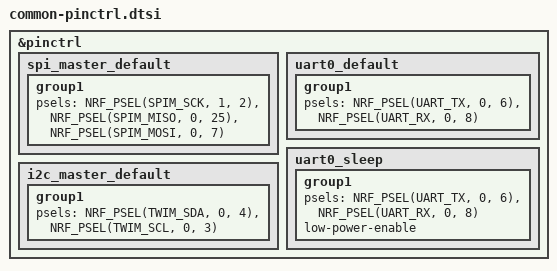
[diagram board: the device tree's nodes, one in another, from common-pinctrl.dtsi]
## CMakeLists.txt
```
#
# Copyright (c) 2018 Nordic Semiconductor
#
# SPDX-License-Identifier: LicenseRef-Nordic-5-Clause
#
cmake_minimum_required(VERSION 3.20.0)

find_package(Zephyr REQUIRED HINTS $ENV{ZEPHYR_BASE})
project(peripheral_uart)

# NORDIC SDK APP START
target_sources(app PRIVATE
  src/main.c
  src/spi.c
  src/BLE.c
  src/timer.c
  src/data.c
)

# NORDIC SDK APP END
```

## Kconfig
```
# Merged Kconfig for chronos-ble-uart project
# This provides menuconfig options for both timing control and BLE features

source "Kconfig.zephyr"

menu "Chronos BLE UART Configuration"

# BLE UART Service Configuration (from peripheral_uart)
config BT_NUS_THREAD_STACK_SIZE
	int "BLE UART thread stack size"
	default 1024
	help
	  Stack size used in each of the two threads handling BLE UART communication

config BT_NUS_UART_BUFFER_SIZE
	int "UART payload buffer element size"
	default 40
	help
	  Size of the payload buffer in each RX and TX FIFO element
	  Increase this if you need to send larger chunks of data

config BT_NUS_SECURITY_ENABLED
	bool "Enable BLE security"
	default y
	select BT_SMP
	help
	  Enable BLE security for the UART service
	  This includes pairing and bonding support

config BT_NUS_UART_RX_WAIT_TIME
	int "Timeout for UART RX complete event"
	default 50000
	help
	  Wait for RX complete event time in microseconds

# Chronos Timing Control Configuration (new section)
menu "Timing Control Configuration"

config CHRONOS_STIM_TIMER_US
	int "Stimulation timer period (microseconds)"
	default 4000000
	help
	  Time between stimulation events in microseconds
	  Default is 4 seconds (4000000 us)

config CHRONOS_EVENT1_OFFSET_US
	int "Event 1 offset from main event (microseconds)"
	default 1000000
	help
	  Time delay for first event after main stimulation

config CHRONOS_EVENT2_OFFSET_US
	int "Event 2 offset from event 1 (microseconds)"
	default 1000000
	help
	  Time delay for second event after event 1

config CHRONOS_EVENT3_OFFSET_US
	int "Event 3 offset from event 2 (microseconds)"
	default 1000000
	help
	  Time delay for third event after event 2

config CHRONOS_USE_PPI
	bool "Use PPI for hardware-timed events"
	default n
	help
	  Use Programmable Peripheral Interconnect for precise timing
	  This reduces CPU involvement and improves timing accuracy

endmenu # Timing Control Configuration

# Storage configuration (auto-selected based on hardware)
config SETTINGS
	default y

config ZMS
	default y if (SOC_FLASH_NRF_RRAM || SOC_FLASH_NRF_MRAM)
	help
	  Use Zephyr Memory Storage for newer flash types

config NVS
	default y if !(SOC_FLASH_NRF_RRAM || SOC_FLASH_NRF_MRAM)
	help
	  Use Non-Volatile Storage for traditional flash

endmenu # Chronos BLE UART Configuration
```

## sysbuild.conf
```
# Sysbuild configuration for nRF5340 dual-core Bluetooth application
# Compatible with nRF Connect SDK v3.0.2

# =============================================================================
# Network Core Configuration
# =============================================================================

# Enable the network core with Bluetooth controller
# This tells sysbuild to build the IPC radio image for the network core
SB_CONFIG_NETCORE_IPC_RADIO=y

# Use HCI IPC for Bluetooth communication between cores
# This enables the Bluetooth host (app core) to controller (net core) interface
SB_CONFIG_NETCORE_IPC_RADIO_BT_HCI_IPC=y

# =============================================================================
# Build Options
# =============================================================================

# Build the network core image
# This ensures both cores are programmed
SB_CONFIG_NETCORE_APP_UPDATE=y

# =============================================================================
# Optional: Bootloader Configuration
# =============================================================================

# For now, we're not using MCUboot
# Enable these later when you need firmware update capability
SB_CONFIG_BOOTLOADER_MCUBOOT=n
```

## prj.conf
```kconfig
#
# Copyright (c) 2018 Nordic Semiconductor
#
# SPDX-License-Identifier: LicenseRef-Nordic-5-Clause
#
##############################################################################
# BLE STACK
##############################################################################
# Enable the UART driver
CONFIG_UART_ASYNC_API=y
CONFIG_NRFX_UARTE0=y
CONFIG_SERIAL=y

CONFIG_GPIO=y

# Make sure printk is printing to the UART console
CONFIG_CONSOLE=y
CONFIG_UART_CONSOLE=y

CONFIG_HEAP_MEM_POOL_SIZE=2048

CONFIG_BT=y
CONFIG_BT_PERIPHERAL=y
CONFIG_BT_DEVICE_NAME="Chronos"
CONFIG_BT_MAX_CONN=1
CONFIG_BT_MAX_PAIRED=1

# Enable the NUS service
CONFIG_BT_NUS=y

# Enable bonding
CONFIG_BT_SETTINGS=y
CONFIG_FLASH=y
CONFIG_FLASH_PAGE_LAYOUT=y
CONFIG_FLASH_MAP=y

# Enable DK LED and Buttons library
CONFIG_DK_LIBRARY=y

CONFIG_SYSTEM_WORKQUEUE_STACK_SIZE=2048
# Config logger
CONFIG_LOG=y
CONFIG_USE_SEGGER_RTT=y
CONFIG_LOG_BACKEND_RTT=n
CONFIG_LOG_BACKEND_UART=y
CONFIG_LOG_PRINTK=y

CONFIG_ASSERT=y

##############################################################################
# SPIM
##############################################################################
CONFIG_NRFX_SPIM1=y
CONFIG_NRFX_QSPI=n
##############################################################################
# TIMER
##############################################################################
CONFIG_NRFX_TIMER0=y
CONFIG_NRFX_TIMER1=y
```

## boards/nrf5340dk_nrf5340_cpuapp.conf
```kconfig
# Board-specific configuration for nRF5340 DK (Application core)
# This file contains Kconfig symbols specific to this board

# Bluetooth configuration specific to nRF5340
# The nRF5340 has a dedicated network core for radio operations
CONFIG_BT_HOST_CRYPTO_PRNG=y
CONFIG_ENTROPY_BT_HCI=n

# If you need board-specific timer configurations
# CONFIG_NRFX_TIMER2=y

# Any other board-specific Kconfig options go here
# Remember: This file should only contain CONFIG_* lines, not device tree content
```

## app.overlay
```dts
/*
 * Application core overlay for chronos_ble_uart project
 * This file contains device tree modifications specific to the application core
 * when running in a multi-core configuration with sysbuild
 */

/* 
 * IPC (Inter-Processor Communication) configuration
 * This is crucial for communication between app and network cores
 */
/ {
    chosen {
        /* 
         * Define which UART to use for Nordic UART Service
         * In dual-core setup, this UART is only accessed by the app core
         */
        nordic,nus-uart = &uart0;
        
        /*
         * Console output - using RTT is recommended for dual-core setups
         * to avoid UART conflicts and reduce interrupt overhead
         */
        zephyr,console = &rtt0;
    };
};

/*
 * Shared memory configuration for IPC
 * This defines how the two cores communicate
 */
&ipc0 {
    status = "okay";
};

/*
 * RAM allocation for shared memory
 * The cores need a common area to exchange messages
 */
&sram0_shared {
    status = "okay";
};

/*
 * Application core specific peripheral configurations
 */

/* Your SPI configuration for DAC control */
&spi1 {
    status = "disabled"; /* Disabled for Zephyr, you're using nrfx directly */
};

/* GPIO controllers for your timing pins */
&gpio0 {
    status = "okay";
};

&gpio1 {
    status = "okay";
};

/* 
 * UART0 configuration for BLE NUS
 * Even though the Bluetooth stack runs on the network core,
 * the UART data is handled by the application core
 */
&uart0 {
    status = "okay";
    current-speed = <115200>;
};
```

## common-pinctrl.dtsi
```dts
/*
 * Pin control configuration for chronos-ble-uart project
 * This file defines how pins are multiplexed for different peripherals
 * 
 * Pin assignments based on your main.c:
 * - SPI: SCK=P1.02, MOSI=P0.07, MISO=P0.25
 * - DAC1 CS: P0.16
 * - DAC2 CS: P0.26
 * - Control pins: P1.00, P1.01, P1.03
 */

&pinctrl {
    /* SPI Master configuration - matching your main.c */
    spi_master_default: spi_master_default {
        group1 {
            psels = <NRF_PSEL(SPIM_SCK, 1, 2)>,    /* P1.02 for SCK */
                    <NRF_PSEL(SPIM_MISO, 0, 25)>,  /* P0.25 for MISO */
                    <NRF_PSEL(SPIM_MOSI, 0, 7)>;    /* P0.07 for MOSI */
        };
    };

    /* UART pins for BLE NUS service */
    uart0_default: uart0_default {
        group1 {
            psels = <NRF_PSEL(UART_TX, 0, 6)>,     /* P0.06 - default TX pin */
                    <NRF_PSEL(UART_RX, 0, 8)>;      /* P0.08 - default RX pin */
        };
    };

    uart0_sleep: uart0_sleep {
        group1 {
            psels = <NRF_PSEL(UART_TX, 0, 6)>,
                    <NRF_PSEL(UART_RX, 0, 8)>;
            low-power-enable;
        };
    };

    /* I2C configurations - keeping for future use */
    i2c_master_default: i2c_master_default {
        group1 {
            psels = <NRF_PSEL(TWIM_SDA, 0, 4)>,    /* Example pins */
                    <NRF_PSEL(TWIM_SCL, 0, 3)>;
        };
    };
};
```

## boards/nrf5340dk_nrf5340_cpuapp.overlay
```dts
/* 
 * Merged device tree overlay for nRF5340 DK application core
 * This combines hardware configurations from both projects
 */

#include "../common-pinctrl.dtsi"

/* We're using nrfx directly for SPI, so disable Zephyr's SPI driver */
&spi1 {
    status = "disabled";
};

/* Enable GPIO controllers (needed for pin control in both projects) */
&gpio0 {
    status = "okay";
};

&gpio1 {
    status = "okay";
};

/* UART configuration for Nordic UART Service
 * This comes from peripheral_uart's app.overlay 
 */
/ {
    chosen {
        /* This tells Zephyr which UART to use for the NUS service */
        nordic,nus-uart = &uart0;
        
        /* Keep the default console on UART0 as well
         * You might want to change this if you need UART0 exclusively for BLE
         * In that case, you could use RTT for console:
         * zephyr,console = &rtt0;
         */
        zephyr,console = &uart0;
    };
};
```

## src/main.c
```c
/*
 * Copyright (c) 2018 Nordic Semiconductor ASA
 *
 * SPDX-License-Identifier: LicenseRef-Nordic-5-Clause
 */

/** @file
 *  @brief Nordic UART Bridge Service (NUS) sample
 */
#include <uart_async_adapter.h>

#include <zephyr/types.h>
#include <zephyr/kernel.h>
#include <zephyr/drivers/uart.h>
#include <zephyr/usb/usb_device.h>

#include <zephyr/device.h>
#include <zephyr/devicetree.h>
#include <soc.h>

#include <zephyr/bluetooth/bluetooth.h>
#include <zephyr/bluetooth/uuid.h>
#include <zephyr/bluetooth/gatt.h>
#include <zephyr/bluetooth/hci.h>

#include <bluetooth/services/nus.h>

#include <dk_buttons_and_leds.h>

#include <zephyr/settings/settings.h>

#include <stdio.h>
#include <string.h>

#include <zephyr/logging/log.h>

#include <nrfx_spim.h>
#include <nrfx_timer.h>
#include <zephyr/sys/atomic.h>

#include "BLE.h"
#include "spi.h"
#include "timer.h"
#include "config.h"

LOG_MODULE_REGISTER(mymain, LOG_LEVEL_DBG);
static void init_clock();
BT_CONN_CB_DEFINE(conn_callbacks) = {
	.connected        = connected,
	.disconnected     = disconnected,
	.recycled         = recycled_cb,
#ifdef CONFIG_BT_NUS_SECURITY_ENABLED
	.security_changed = security_changed,
#endif
};

static struct bt_nus_cb nus_cb = {
	.received = bt_receive_cb,
};

static void init_misc_pins(void) {
    // Configure P0.16 as output (DAC1 CS)
    nrf_gpio_cfg_output(NRF_GPIO_PIN_MAP(0, 16));
    nrf_gpio_pin_set(NRF_GPIO_PIN_MAP(0, 16));  // Set high (inactive)
    
    // Configure P0.26 as output (DAC2 CS)
    nrf_gpio_cfg_output(NRF_GPIO_PIN_MAP(0, 26));
    nrf_gpio_pin_set(NRF_GPIO_PIN_MAP(0, 26));  // Set high (inactive)
    
    nrf_gpio_cfg_output(NRF_GPIO_PIN_MAP(1, 3));
    nrf_gpio_pin_clear(NRF_GPIO_PIN_MAP(1, 3)); // set low

    nrf_gpio_cfg_output(NRF_GPIO_PIN_MAP(1, 0));
    nrf_gpio_pin_clear(NRF_GPIO_PIN_MAP(1, 0)); // set low

    nrf_gpio_cfg_output(NRF_GPIO_PIN_MAP(1, 1));
    nrf_gpio_pin_clear(NRF_GPIO_PIN_MAP(1, 1)); // set low
}

int main(void)
{
    #if defined(__ZEPHYR__)
        IRQ_CONNECT(NRFX_IRQ_NUMBER_GET(NRF_TIMER_INST_GET(TIMER_INST_IDX)), IRQ_PRIO_LOWEST,
                    NRFX_TIMER_INST_HANDLER_GET(TIMER_INST_IDX), 0, 0);
        IRQ_CONNECT(NRFX_IRQ_NUMBER_GET(NRF_SPIM_INST_GET(SPIM_INST_IDX)), IRQ_PRIO_LOWEST,
                    NRFX_SPIM_INST_HANDLER_GET(SPIM_INST_IDX), 0, 0);
    #endif

    init_clock();
    init_misc_pins();
    spi_init();
    timer_init();
    measurement_timer_init();
	int blink_status = 0;
	int err = 0;
    uint32_t experiment_counter = 0;
    
	configure_gpio();

	err = uart_init();
	if (err) {
		error();
	}

	if (IS_ENABLED(CONFIG_BT_NUS_SECURITY_ENABLED)) {
		err = bt_conn_auth_cb_register(&conn_auth_callbacks);
		if (err) {
			LOG_ERR("Failed to register authorization callbacks. (err: %d)", err);
			return 0;
		}

		err = bt_conn_auth_info_cb_register(&conn_auth_info_callbacks);
		if (err) {
			LOG_ERR("Failed to register authorization info callbacks. (err: %d)", err);
			return 0;
		}
	}

	err = bt_enable(NULL);
	if (err) {
		error();
	}

	LOG_INF("Bluetooth initialized");

	k_sem_give(&ble_init_ok);

	if (IS_ENABLED(CONFIG_SETTINGS)) {
		settings_load();
	}

	err = bt_nus_init(&nus_cb);
	if (err) {
		LOG_ERR("Failed to initialize UART service (err: %d)", err);
		return 0;
	}

	k_work_init(&adv_work, adv_work_handler);
	advertising_start();

	for (;;) {
		dk_set_led(RUN_STATUS_LED, (++blink_status) % 2);
		//k_sleep(K_MSEC(RUN_LED_BLINK_INTERVAL));
        k_msleep(10000);
        if(MEASURE_TIMER ==1){
            experiment_counter += 10;
            error_data my_error_data;
            get_error_data(&my_error_data);
            printf("Counter: %i Elapsed: %is\nEvent0 running error: %lu avg error: %lu max error: %lu\nEvents1-3 running error: %lu avg error: %lu max error: %lu, %lu, %lu\n", 
                my_error_data.mycounter, 
                experiment_counter,
                my_error_data.event0_error,
                (my_error_data.event0_error/my_error_data.mycounter), 
                my_error_data.event0_max,
                my_error_data.myerror,
                (my_error_data.myerror/my_error_data.mycounter),
                my_error_data.event1_max,
                my_error_data.event2_max,
                my_error_data.event3_max);
        }
	}
}

K_THREAD_DEFINE(ble_write_thread_id, STACKSIZE, ble_write_thread, NULL, NULL,
		NULL, PRIORITY, 0, 0);

static void init_clock() {
	// select the clock source: HFINT (high frequency internal oscillator) or HFXO (external 32 MHz crystal)
	NRF_CLOCK_S->HFCLKSRC = (CLOCK_HFCLKSRC_SRC_HFINT << CLOCK_HFCLKSRC_SRC_Pos);

    // start the clock, and wait to verify that it is running
    NRF_CLOCK_S->TASKS_HFCLKSTART = 1;
    while (NRF_CLOCK_S->EVENTS_HFCLKSTARTED == 0);
    NRF_CLOCK_S->EVENTS_HFCLKSTARTED = 0;
}
```

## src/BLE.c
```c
#include <uart_async_adapter.h>

#include <zephyr/types.h>
#include <zephyr/kernel.h>
#include <zephyr/drivers/uart.h>
#include <zephyr/usb/usb_device.h>

#include <zephyr/device.h>
#include <zephyr/devicetree.h>
#include <soc.h>

#include <zephyr/bluetooth/bluetooth.h>
#include <zephyr/bluetooth/uuid.h>
#include <zephyr/bluetooth/gatt.h>
#include <zephyr/bluetooth/hci.h>

#include <bluetooth/services/nus.h>

#include <dk_buttons_and_leds.h>

#include <zephyr/settings/settings.h>

#include <stdio.h>
#include <string.h>

#include <zephyr/logging/log.h>
#include "BLE.h"
#include "data.h"

LOG_MODULE_REGISTER(LOG_MODULE_NAME);
K_SEM_DEFINE(ble_init_ok, 0, 1);
const struct device *uart = DEVICE_DT_GET(DT_CHOSEN(nordic_nus_uart));
struct k_work_delayable uart_work;
const struct bt_data ad[] = {
	BT_DATA_BYTES(BT_DATA_FLAGS, (BT_LE_AD_GENERAL | BT_LE_AD_NO_BREDR)),
	BT_DATA(BT_DATA_NAME_COMPLETE, DEVICE_NAME, DEVICE_NAME_LEN),
};
const size_t ad_len = ARRAY_SIZE(ad);
const struct bt_data sd[] = {
	BT_DATA_BYTES(BT_DATA_UUID128_ALL, BT_UUID_NUS_VAL),
};
const size_t sd_len = ARRAY_SIZE(sd);
struct k_work adv_work;
struct bt_conn *current_conn;
struct bt_conn *auth_conn;
static K_FIFO_DEFINE(fifo_uart_tx_data);
static K_FIFO_DEFINE(fifo_uart_rx_data);
bool ble_data_ready = false;

void uart_work_handler(struct k_work *item)
{
	struct uart_data_t *buf;

	buf = k_malloc(sizeof(*buf));
	if (buf) {
		buf->len = 0;
	} else {
		LOG_WRN("Not able to allocate UART receive buffer");
		k_work_reschedule(&uart_work, UART_WAIT_FOR_BUF_DELAY);
		return;
	}

	uart_rx_enable(uart, buf->data, sizeof(buf->data), UART_WAIT_FOR_RX);
}

bool uart_test_async_api(const struct device *dev)
{
	const struct uart_driver_api *api =
			(const struct uart_driver_api *)dev->api;

	return (api->callback_set != NULL);
}

void adv_work_handler(struct k_work *work)
{
	int err = bt_le_adv_start(BT_LE_ADV_CONN_FAST_2, ad, ad_len, sd, sd_len);

	if (err) {
		LOG_ERR("Advertising failed to start (err %d)", err);
		return;
	}

	LOG_INF("Advertising successfully started");
}

void advertising_start(void)
{
	k_work_submit(&adv_work);
}

void connected(struct bt_conn *conn, uint8_t err)
{
	char addr[BT_ADDR_LE_STR_LEN];

	if (err) {
		LOG_ERR("Connection failed, err 0x%02x %s", err, bt_hci_err_to_str(err));
		return;
	}

	bt_addr_le_to_str(bt_conn_get_dst(conn), addr, sizeof(addr));
	LOG_INF("Connected %s", addr);

	current_conn = bt_conn_ref(conn);

	dk_set_led_on(CON_STATUS_LED);
}

void disconnected(struct bt_conn *conn, uint8_t reason)
{
	char addr[BT_ADDR_LE_STR_LEN];

	bt_addr_le_to_str(bt_conn_get_dst(conn), addr, sizeof(addr));

	LOG_INF("Disconnected: %s, reason 0x%02x %s", addr, reason, bt_hci_err_to_str(reason));

	if (auth_conn) {
		bt_conn_unref(auth_conn);
		auth_conn = NULL;
	}

	if (current_conn) {
		bt_conn_unref(current_conn);
		current_conn = NULL;
		dk_set_led_off(CON_STATUS_LED);
	}
}

void recycled_cb(void)
{
	LOG_INF("Connection object available from previous conn. Disconnect is complete!");
	advertising_start();
}

#ifdef CONFIG_BT_NUS_SECURITY_ENABLED
void security_changed(struct bt_conn *conn, bt_security_t level,
			     enum bt_security_err err)
{
	char addr[BT_ADDR_LE_STR_LEN];

	bt_addr_le_to_str(bt_conn_get_dst(conn), addr, sizeof(addr));

	if (!err) {
		LOG_INF("Security changed: %s level %u", addr, level);
	} else {
		LOG_WRN("Security failed: %s level %u err %d %s", addr, level, err,
			bt_security_err_to_str(err));
	}
}
#endif /* CONFIG_BT_NUS_SECURITY_ENABLED */

#if defined(CONFIG_BT_NUS_SECURITY_ENABLED)
void auth_passkey_display(struct bt_conn *conn, unsigned int passkey)
{
	char addr[BT_ADDR_LE_STR_LEN];

	bt_addr_le_to_str(bt_conn_get_dst(conn), addr, sizeof(addr));

	LOG_INF("Passkey for %s: %06u", addr, passkey);
}

void auth_passkey_confirm(struct bt_conn *conn, unsigned int passkey)
{
	char addr[BT_ADDR_LE_STR_LEN];

	auth_conn = bt_conn_ref(conn);

	bt_addr_le_to_str(bt_conn_get_dst(conn), addr, sizeof(addr));

	LOG_INF("Passkey for %s: %06u", addr, passkey);

	if (IS_ENABLED(CONFIG_SOC_SERIES_NRF54HX) || IS_ENABLED(CONFIG_SOC_SERIES_NRF54LX)) {
		LOG_INF("Press Button 0 to confirm, Button 1 to reject.");
	} else {
		LOG_INF("Press Button 1 to confirm, Button 2 to reject.");
	}
}


void auth_cancel(struct bt_conn *conn)
{
	char addr[BT_ADDR_LE_STR_LEN];

	bt_addr_le_to_str(bt_conn_get_dst(conn), addr, sizeof(addr));

	LOG_INF("Pairing cancelled: %s", addr);
}


void pairing_complete(struct bt_conn *conn, bool bonded)
{
	char addr[BT_ADDR_LE_STR_LEN];

	bt_addr_le_to_str(bt_conn_get_dst(conn), addr, sizeof(addr));

	LOG_INF("Pairing completed: %s, bonded: %d", addr, bonded);
}


void pairing_failed(struct bt_conn *conn, enum bt_security_err reason)
{
	char addr[BT_ADDR_LE_STR_LEN];

	bt_addr_le_to_str(bt_conn_get_dst(conn), addr, sizeof(addr));

	LOG_INF("Pairing failed conn: %s, reason %d %s", addr, reason,
		bt_security_err_to_str(reason));
}

struct bt_conn_auth_cb conn_auth_callbacks = {
	.passkey_display = auth_passkey_display,
	.passkey_confirm = auth_passkey_confirm,
	.cancel = auth_cancel,
};

struct bt_conn_auth_info_cb conn_auth_info_callbacks = {
	.pairing_complete = pairing_complete,
	.pairing_failed = pairing_failed
};
#else
struct bt_conn_auth_cb conn_auth_callbacks;
struct bt_conn_auth_info_cb conn_auth_info_callbacks;
#endif /* CONFIG_BT_NUS_SECURITY_ENABLED */

#ifdef CONFIG_BT_NUS_SECURITY_ENABLED
void num_comp_reply(bool accept)
{
	if (accept) {
		bt_conn_auth_passkey_confirm(auth_conn);
		LOG_INF("Numeric Match, conn %p", (void *)auth_conn);
	} else {
		bt_conn_auth_cancel(auth_conn);
		LOG_INF("Numeric Reject, conn %p", (void *)auth_conn);
	}

	bt_conn_unref(auth_conn);
	auth_conn = NULL;
}

void button_changed(uint32_t button_state, uint32_t has_changed)
{
	uint32_t buttons = button_state & has_changed;

	if (auth_conn) {
		if (buttons & KEY_PASSKEY_ACCEPT) {
			num_comp_reply(true);
		}

		if (buttons & KEY_PASSKEY_REJECT) {
			num_comp_reply(false);
		}
	}
}
#endif /* CONFIG_BT_NUS_SECURITY_ENABLED */

void configure_gpio(void)
{
	int err;

#ifdef CONFIG_BT_NUS_SECURITY_ENABLED
	err = dk_buttons_init(button_changed);
	if (err) {
		LOG_ERR("Cannot init buttons (err: %d)", err);
	}
#endif /* CONFIG_BT_NUS_SECURITY_ENABLED */

	err = dk_leds_init();
	if (err) {
		LOG_ERR("Cannot init LEDs (err: %d)", err);
	}
}

void error(void)
{
	dk_set_leds_state(DK_ALL_LEDS_MSK, DK_NO_LEDS_MSK);

	while (true) {
		/* Spin for ever */
		k_sleep(K_MSEC(1000));
	}
}

void bt_receive_cb(struct bt_conn *conn, const uint8_t *const data,
			  uint16_t len)
{
    // Store the data
    if (len <= BLE_DATA_BUFFER_SIZE) {
        memcpy(ble_received_data, data, len);
        ble_data_length = len;
        ble_data_ready = true;
    }

    process_received_data(&settings, ble_received_data, ble_data_length);
	int err;
	char addr[BT_ADDR_LE_STR_LEN] = {0};

	bt_addr_le_to_str(bt_conn_get_dst(conn), addr, ARRAY_SIZE(addr));

	LOG_INF("Received data from: %s: %X", addr, ble_received_data);
}

void uart_cb(const struct device *dev, struct uart_event *evt, void *user_data)
{
	ARG_UNUSED(dev);

	static size_t aborted_len;
	struct uart_data_t *buf;
	static uint8_t *aborted_buf;
	static bool disable_req;

	switch (evt->type) {
	case UART_TX_DONE:
		LOG_DBG("UART_TX_DONE");
		if ((evt->data.tx.len == 0) ||
		    (!evt->data.tx.buf)) {
			return;
		}

		if (aborted_buf) {
			buf = CONTAINER_OF(aborted_buf, struct uart_data_t,
					   data[0]);
			aborted_buf = NULL;
			aborted_len = 0;
		} else {
			buf = CONTAINER_OF(evt->data.tx.buf, struct uart_data_t,
					   data[0]);
		}

		k_free(buf);

		buf = k_fifo_get(&fifo_uart_tx_data, K_NO_WAIT);
		if (!buf) {
			return;
		}

		if (uart_tx(uart, buf->data, buf->len, SYS_FOREVER_MS)) {
			LOG_WRN("Failed to send data over UART");
		}

		break;

	case UART_RX_RDY:
		LOG_DBG("UART_RX_RDY");
		buf = CONTAINER_OF(evt->data.rx.buf, struct uart_data_t, data[0]);
		buf->len += evt->data.rx.len;

		if (disable_req) {
			return;
		}

		if ((evt->data.rx.buf[buf->len - 1] == '\n') ||
		    (evt->data.rx.buf[buf->len - 1] == '\r')) {
			disable_req = true;
			uart_rx_disable(uart);
		}

		break;

	case UART_RX_DISABLED:
		LOG_DBG("UART_RX_DISABLED");
		disable_req = false;

		buf = k_malloc(sizeof(*buf));
		if (buf) {
			buf->len = 0;
		} else {
			LOG_WRN("Not able to allocate UART receive buffer");
			k_work_reschedule(&uart_work, UART_WAIT_FOR_BUF_DELAY);
			return;
		}

		uart_rx_enable(uart, buf->data, sizeof(buf->data),
			       UART_WAIT_FOR_RX);

		break;

	case UART_RX_BUF_REQUEST:
		LOG_DBG("UART_RX_BUF_REQUEST");
		buf = k_malloc(sizeof(*buf));
		if (buf) {
			buf->len = 0;
			uart_rx_buf_rsp(uart, buf->data, sizeof(buf->data));
		} else {
			LOG_WRN("Not able to allocate UART receive buffer");
		}

		break;

	case UART_RX_BUF_RELEASED:
		LOG_DBG("UART_RX_BUF_RELEASED");
		buf = CONTAINER_OF(evt->data.rx_buf.buf, struct uart_data_t,
				   data[0]);

		if (buf->len > 0) {
			k_fifo_put(&fifo_uart_rx_data, buf);
		} else {
			k_free(buf);
		}

		break;

	case UART_TX_ABORTED:
		LOG_DBG("UART_TX_ABORTED");
		if (!aborted_buf) {
			aborted_buf = (uint8_t *)evt->data.tx.buf;
		}

		aborted_len += evt->data.tx.len;
		buf = CONTAINER_OF((void *)aborted_buf, struct uart_data_t,
				   data);

		uart_tx(uart, &buf->data[aborted_len],
			buf->len - aborted_len, SYS_FOREVER_MS);

		break;

	default:
		break;
	}
}

int uart_init(void)
{
	int err;
	int pos;
	struct uart_data_t *rx;
	struct uart_data_t *tx;

	if (!device_is_ready(uart)) {
		return -ENODEV;
	}

	if (IS_ENABLED(CONFIG_USB_DEVICE_STACK)) {
		err = usb_enable(NULL);
		if (err && (err != -EALREADY)) {
			LOG_ERR("Failed to enable USB");
			return err;
		}
	}

	rx = k_malloc(sizeof(*rx));
	if (rx) {
		rx->len = 0;
	} else {
		return -ENOMEM;
	}

	k_work_init_delayable(&uart_work, uart_work_handler);


	if (IS_ENABLED(CONFIG_UART_ASYNC_ADAPTER) && !uart_test_async_api(uart)) {
		/* Implement API adapter */
		uart_async_adapter_init(async_adapter, uart);
		uart = async_adapter;
	}

	err = uart_callback_set(uart, uart_cb, NULL);
	if (err) {
		k_free(rx);
		LOG_ERR("Cannot initialize UART callback");
		return err;
	}

	if (IS_ENABLED(CONFIG_UART_LINE_CTRL)) {
		LOG_INF("Wait for DTR");
		while (true) {
			uint32_t dtr = 0;

			uart_line_ctrl_get(uart, UART_LINE_CTRL_DTR, &dtr);
			if (dtr) {
				break;
			}
			/* Give CPU resources to low priority threads. */
			k_sleep(K_MSEC(100));
		}
		LOG_INF("DTR set");
		err = uart_line_ctrl_set(uart, UART_LINE_CTRL_DCD, 1);
		if (err) {
			LOG_WRN("Failed to set DCD, ret code %d", err);
		}
		err = uart_line_ctrl_set(uart, UART_LINE_CTRL_DSR, 1);
		if (err) {
			LOG_WRN("Failed to set DSR, ret code %d", err);
		}
	}

	tx = k_malloc(sizeof(*tx));

	if (tx) {
		pos = snprintf(tx->data, sizeof(tx->data),
			       "Starting Nordic UART service sample\r\n");

		if ((pos < 0) || (pos >= sizeof(tx->data))) {
			k_free(rx);
			k_free(tx);
			LOG_ERR("snprintf returned %d", pos);
			return -ENOMEM;
		}

		tx->len = pos;
	} else {
		k_free(rx);
		return -ENOMEM;
	}

	err = uart_tx(uart, tx->data, tx->len, SYS_FOREVER_MS);
	if (err) {
		k_free(rx);
		k_free(tx);
		LOG_ERR("Cannot display welcome message (err: %d)", err);
		return err;
	}

	err = uart_rx_enable(uart, rx->data, sizeof(rx->data), UART_WAIT_FOR_RX);
	if (err) {
		LOG_ERR("Cannot enable uart reception (err: %d)", err);
		/* Free the rx buffer only because the tx buffer will be handled in the callback */
		k_free(rx);
	}

	return err;
}

void ble_write_thread(void)
{
	/* Don't go any further until BLE is initialized */
	k_sem_take(&ble_init_ok, K_FOREVER);
	struct uart_data_t nus_data = {
		.len = 0,
	};

	for (;;) {
		/* Wait indefinitely for data to be sent over bluetooth */
		struct uart_data_t *buf = k_fifo_get(&fifo_uart_rx_data,
						     K_FOREVER);

		int plen = MIN(sizeof(nus_data.data) - nus_data.len, buf->len);
		int loc = 0;

		while (plen > 0) {
			memcpy(&nus_data.data[nus_data.len], &buf->data[loc], plen);
			nus_data.len += plen;
			loc += plen;

			if (nus_data.len >= sizeof(nus_data.data) ||
			   (nus_data.data[nus_data.len - 1] == '\n') ||
			   (nus_data.data[nus_data.len - 1] == '\r')) {
				if (bt_nus_send(NULL, nus_data.data, nus_data.len)) {
					LOG_WRN("Failed to send data over BLE connection");
				}
				nus_data.len = 0;
			}

			plen = MIN(sizeof(nus_data.data), buf->len - loc);
		}

		k_free(buf);
	}
}
```

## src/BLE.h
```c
#ifndef BLE_H
#define BLE_H

#include <zephyr/types.h>
#include <zephyr/device.h>

#define LOG_MODULE_NAME peripheral_uart

#define STACKSIZE CONFIG_BT_NUS_THREAD_STACK_SIZE
#define PRIORITY 7

#define DEVICE_NAME CONFIG_BT_DEVICE_NAME
#define DEVICE_NAME_LEN	(sizeof(DEVICE_NAME) - 1)

#define RUN_STATUS_LED DK_LED1
#define RUN_LED_BLINK_INTERVAL 1000

#define CON_STATUS_LED DK_LED2

#define KEY_PASSKEY_ACCEPT DK_BTN1_MSK
#define KEY_PASSKEY_REJECT DK_BTN2_MSK

#define UART_BUF_SIZE CONFIG_BT_NUS_UART_BUFFER_SIZE
#define UART_WAIT_FOR_BUF_DELAY K_MSEC(50)
#define UART_WAIT_FOR_RX CONFIG_BT_NUS_UART_RX_WAIT_TIME

#ifdef CONFIG_UART_ASYNC_ADAPTER
UART_ASYNC_ADAPTER_INST_DEFINE(async_adapter);
#else
#define async_adapter NULL
#endif // CONFIG_UART_ASYNC_ADAPTER

extern struct k_sem ble_init_ok;
extern struct k_work_delayable uart_work;
extern const struct device *uart;
extern struct k_work adv_work;
extern struct bt_conn *current_conn;
extern struct bt_conn *auth_conn;
extern const struct bt_data ad[];
extern const struct bt_data sd[];
extern const size_t ad_len;
extern const size_t sd_len;
extern bool ble_data_ready;
struct uart_data_t {
    void *fifo_reserved;
    uint8_t data[UART_BUF_SIZE];
    uint16_t len;
};

void uart_work_handler(struct k_work *item);
bool uart_test_async_api(const struct device *dev);
void adv_work_handler(struct k_work *work);
void advertising_start(void);
void connected(struct bt_conn *conn, uint8_t err);
void disconnected(struct bt_conn *conn, uint8_t reason);
void recycled_cb(void);
void configure_gpio(void);
void error(void);
void bt_receive_cb(struct bt_conn *conn, const uint8_t *const data,
			  uint16_t len);
void uart_cb(const struct device *dev, struct uart_event *evt, void *user_data);
int uart_init(void);
void ble_write_thread(void);

#ifdef CONFIG_BT_NUS_SECURITY_ENABLED
void security_changed(struct bt_conn *conn, bt_security_t level,
                 enum bt_security_err err);
#endif /* CONFIG_BT_NUS_SECURITY_ENABLED */

#if defined(CONFIG_BT_NUS_SECURITY_ENABLED)
void auth_passkey_display(struct bt_conn *conn, unsigned int passkey);
void auth_passkey_confirm(struct bt_conn *conn, unsigned int passkey);
void auth_cancel(struct bt_conn *conn);
void pairing_complete(struct bt_conn *conn, bool bonded);
void pairing_failed(struct bt_conn *conn, enum bt_security_err reason);
extern struct bt_conn_auth_cb conn_auth_callbacks;
extern struct bt_conn_auth_info_cb conn_auth_info_callbacks;
#else
extern struct bt_conn_auth_cb conn_auth_callbacks;
extern struct bt_conn_auth_info_cb conn_auth_info_callbacks;
#endif /* CONFIG_BT_NUS_SECURITY_ENABLED */

#ifdef CONFIG_BT_NUS_SECURITY_ENABLED
void num_comp_reply(bool accept);
void button_changed(uint32_t button_state, uint32_t has_changed);
#endif /* CONFIG_BT_NUS_SECURITY_ENABLED */

#endif /* BLE_H */
```

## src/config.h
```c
#ifndef CONFIG_H
#define CONFIG_H

#define MEASURE_TIMER 0 // 1: testing timer accuracy with built-in timer 
                        // 0: disable measurement timer
#define SPI_VERBOSE 0   // 1: enable verbose SPI logging
#endif // CONFIG_H
```

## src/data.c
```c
#include <zephyr/types.h>
#include <string.h>
#include "data.h"
#include "timer.h"
#include "spi.h"

stim_setting settings;
uint8_t ble_received_data[BLE_DATA_BUFFER_SIZE];
uint16_t ble_data_length;

void process_received_data(stim_setting *settings, uint8_t *ble_received_data, uint16_t ble_data_length) {
    if (ble_data_length == sizeof(stim_setting)) {
        memcpy(settings, ble_received_data, sizeof(stim_setting));
        // settings = (stim_setting *)ble_received_data;
        // Process the settings as needed
        // For example, you can print them or use them in your application logic
        printf("Received settings:\n");
        printf("DAC Amplitude: %u\n", settings->DAC_amplitude);
        printf("Pulse Width: %u us\n", settings->pulse_width);
        printf("Frequency: %u Hz\n", settings->frequency);
        if (settings->frequency > 0) {
            update_stim_frequency(settings->frequency);
        } else {
            printf("Warning: Received frequency is 0 Hz, timer not updated\n");
        }
        if (settings->pulse_width > 0) {
            update_pulse_width(settings->pulse_width);
        } else {
            printf("Warning: Received pulse width is 0 us, pulse width not updated\n");
        }
        update_dac1_amplitude(settings->DAC_amplitude);
        //! This doesn't negate the amplitude yet
        update_dac2_amplitude(settings->DAC_amplitude);
    } else {
        printf("Received data length mismatch: expected %zu, got %u\n",
               sizeof(stim_setting), ble_data_length);
    }
}
```

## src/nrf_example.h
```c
/*
 * Copyright (c) 2022 - 2023, Nordic Semiconductor ASA
 * All rights reserved.
 *
 * SPDX-License-Identifier: BSD-3-Clause
 *
 * Redistribution and use in source and binary forms, with or without
 * modification, are permitted provided that the following conditions are met:
 *
 * 1. Redistributions of source code must retain the above copyright notice, this
 *    list of conditions and the following disclaimer.
 *
 * 2. Redistributions in binary form must reproduce the above copyright
 *    notice, this list of conditions and the following disclaimer in the
 *    documentation and/or other materials provided with the distribution.
 *
 * 3. Neither the name of the copyright holder nor the names of its
 *    contributors may be used to endorse or promote products derived from this
 *    software without specific prior written permission.
 *
 * THIS SOFTWARE IS PROVIDED BY THE COPYRIGHT HOLDERS AND CONTRIBUTORS "AS IS"
 * AND ANY EXPRESS OR IMPLIED WARRANTIES, INCLUDING, BUT NOT LIMITED TO, THE
 * IMPLIED WARRANTIES OF MERCHANTABILITY AND FITNESS FOR A PARTICULAR PURPOSE
 * ARE DISCLAIMED. IN NO EVENT SHALL THE COPYRIGHT HOLDER OR CONTRIBUTORS BE
 * LIABLE FOR ANY DIRECT, INDIRECT, INCIDENTAL, SPECIAL, EXEMPLARY, OR
 * CONSEQUENTIAL DAMAGES (INCLUDING, BUT NOT LIMITED TO, PROCUREMENT OF
 * SUBSTITUTE GOODS OR SERVICES; LOSS OF USE, DATA, OR PROFITS; OR BUSINESS
 * INTERRUPTION) HOWEVER CAUSED AND ON ANY THEORY OF LIABILITY, WHETHER IN
 * CONTRACT, STRICT LIABILITY, OR TORT (INCLUDING NEGLIGENCE OR OTHERWISE)
 * ARISING IN ANY WAY OUT OF THE USE OF THIS SOFTWARE, EVEN IF ADVISED OF THE
 * POSSIBILITY OF SUCH DAMAGE.
 */

#ifndef NRFX_EXAMPLE_H__
#define NRFX_EXAMPLE_H__

#if defined(__ZEPHYR__)
#include <zephyr/logging/log_ctrl.h>
#define NRFX_EXAMPLE_LOG_INIT()    LOG_INIT()
#define NRFX_EXAMPLE_LOG_PROCESS() while (LOG_PROCESS())
#else
#define NRFX_EXAMPLE_LOG_INIT()
#define NRFX_EXAMPLE_LOG_PROCESS()
#endif

#if defined(NRF52_SERIES)
#define LOOPBACK_PIN_1A 3
#define LOOPBACK_PIN_1B 31
#define LOOPBACK_PIN_2A 4
#define LOOPBACK_PIN_2B 30
#define LOOPBACK_PIN_3A 28
#define LOOPBACK_PIN_3B 29
#define LOOPBACK_PIN_4A 26
#define LOOPBACK_PIN_4B 27
#define ANALOG_INPUT_A0 1
#define ANALOG_INPUT_A1 2
#define ANALOG_INPUT_A2 4
#if defined(NRF52832_XXAA) || defined (NRF52832_XXAB)
#define LED1_PIN        17
#define LED2_PIN        18
#define LED3_PIN        19
#define LED4_PIN        20
#else
#define LED1_PIN        13
#define LED2_PIN        14
#define LED3_PIN        15
#define LED4_PIN        16
#endif
#elif defined(NRF53_SERIES)
#define LOOPBACK_PIN_1A 4
#define LOOPBACK_PIN_1B 26
#define LOOPBACK_PIN_2A 5
#define LOOPBACK_PIN_2B 25
#define LOOPBACK_PIN_3A 6
#define LOOPBACK_PIN_3B 7
#define LOOPBACK_PIN_4A 34
#define LOOPBACK_PIN_4B 35
#define ANALOG_INPUT_A0 0
#define ANALOG_INPUT_A1 1
#define ANALOG_INPUT_A2 2
#define LED1_PIN        28
#define LED2_PIN        29
#define LED3_PIN        30
#define LED4_PIN        31
#elif defined(NRF91_SERIES)
#define LOOPBACK_PIN_1A 14
#define LOOPBACK_PIN_1B 19
#define LOOPBACK_PIN_2A 15
#define LOOPBACK_PIN_2B 18
#define LOOPBACK_PIN_3A 16
#define LOOPBACK_PIN_3B 17
#define LOOPBACK_PIN_4A 30
#define LOOPBACK_PIN_4B 31
#define ANALOG_INPUT_A0 1
#define ANALOG_INPUT_A1 2
#define ANALOG_INPUT_A2 3
#define LED1_PIN        2
#define LED2_PIN        3
#define LED3_PIN        4
#define LED4_PIN        5
#else
#error "Unknown device."
#endif

#define ANALOG_INPUT_TO_SAADC_AIN(x) ((x) + 1)

#define ANALOG_INPUT_TO_COMP_AIN(x) (x)

#endif // NRFX_EXAMPLE_H__
```

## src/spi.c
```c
#include <nrfx_spim.h>
#include <zephyr/kernel.h>
#include <zephyr/device.h>
#include <hal/nrf_gpio.h>
#include "spi.h"
#include "config.h"

static nrfx_spim_t spim_inst = NRFX_SPIM_INSTANCE(SPIM_INST_IDX);
static void spim_handler(nrfx_spim_evt_t const * p_event, void * p_context);
uint8_t dac1_buf_tx[DAC_TX_LEN] = {0x52, 0x53};
uint8_t dac2_buf_tx[DAC_TX_LEN] = {0x54, 0x55};
uint8_t dac1_buf_rx[DAC_RX_LEN];
uint8_t dac2_buf_rx[DAC_RX_LEN];
void update_dac1_amplitude(uint16_t amplitude) {
    dac1_buf_tx[0] = (amplitude >> 8) & 0xFF;  // MSB
    dac1_buf_tx[1] = amplitude & 0xFF;         // LSB
    
    printf("DAC1 amplitude updated to %u (0x%02X 0x%02X)\n", 
           amplitude, dac1_buf_tx[0], dac1_buf_tx[1]);
}

void update_dac2_amplitude(uint16_t amplitude) {
    uint16_t opposite_amplitude;
    if (amplitude == 0x0000) {
        opposite_amplitude = 0xFFFF;  // Most negative → Most positive
    } else {
        opposite_amplitude = (uint16_t)(0x10000UL - amplitude);
    }
    
    dac2_buf_tx[0] = (opposite_amplitude >> 8) & 0xFF;  // MSB
    dac2_buf_tx[1] = opposite_amplitude & 0xFF;         // LSB
    
    printf("DAC2 amplitude updated to opposite of %u: %u (0x%02X 0x%02X)\n", 
           amplitude, opposite_amplitude, dac2_buf_tx[0], dac2_buf_tx[1]);
}

void cs_select(uint32_t pin_number) {
    nrf_gpio_pin_clear(pin_number);  // Drive CS low (active)
}

void cs_deselect(uint32_t pin_number) {
    nrf_gpio_pin_set(pin_number);     // Drive CS high (inactive)
}

void spi_write_dac1(uint8_t *tx_data, uint8_t *rx_data) {
    // Select DAC1
    cs_select(DAC1_CS_PIN);
    memset(rx_data, 0, DAC_RX_LEN); // Clear RX buffer
    // Prepare transfer descriptor
    nrfx_spim_xfer_desc_t xfer_desc = NRFX_SPIM_XFER_TRX(tx_data, DAC_TX_LEN, rx_data, DAC_RX_LEN);
    
    // Perform the transfer
    nrfx_err_t err = nrfx_spim_xfer(&spim_inst, &xfer_desc, 0);
    if(err != NRFX_SUCCESS){
        printf("SPI ERROR\n");
    }
    cs_deselect(DAC1_CS_PIN);
}

void spi_write_dac2(uint8_t *tx_data, uint8_t *rx_data) {
    // Select DAC1
    cs_select(DAC2_CS_PIN);
    memset(rx_data, 0, DAC_RX_LEN); // Clear RX buffer
    // Prepare transfer descriptor
    nrfx_spim_xfer_desc_t xfer_desc = NRFX_SPIM_XFER_TRX(tx_data, DAC_TX_LEN, rx_data, DAC_RX_LEN);
    
    // Perform the transfer
    nrfx_err_t err = nrfx_spim_xfer(&spim_inst, &xfer_desc, 0);
    if(err != NRFX_SUCCESS){
        printf("SPI ERROR\n");
    }
    cs_deselect(DAC2_CS_PIN);
}
void spi_init(){
    nrfx_spim_config_t spim_config = NRFX_SPIM_DEFAULT_CONFIG(SCK_PIN,
                                                              MOSI_PIN,
                                                              MISO_PIN,
                                                              NRF_SPIM_PIN_NOT_CONNECTED);

    spim_config.frequency = 8000000;
    nrfx_err_t status = nrfx_spim_init(&spim_inst, &spim_config, spim_handler, NULL);
    if (status == NRFX_SUCCESS) {
        printf("SPI initialized successfully on SPIM%d\n", SPIM_INST_IDX);
        printf("  SCK: P%d.%02d\n", (SCK_PIN >> 5), (SCK_PIN & 0x1F));
        printf("  MOSI: P%d.%02d\n", (MOSI_PIN >> 5), (MOSI_PIN & 0x1F)); 
        printf("  MISO: P%d.%02d\n", (MISO_PIN >> 5), (MISO_PIN & 0x1F));
    } else {
        printf("SPI initialization failed with error: %d\n", status);
    }
}

static void spim_handler(nrfx_spim_evt_t const * p_event, void * p_context){
    if ((p_event->type == NRFX_SPIM_EVENT_DONE)&& (SPI_VERBOSE == 1)){
        printf("Message received: %02X\n", p_event->xfer_desc.p_rx_buffer);
    }
}
```

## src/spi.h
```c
#ifndef SPI_H
#define SPI_H
#include <zephyr/kernel.h>
#include <zephyr/device.h>
#include <hal/nrf_gpio.h>

#define DAC1_CS_PIN 16  // P0.16
#define DAC2_CS_PIN 26  // P0.26
#define DAC_TX_LEN			2
#define DAC_RX_LEN			2

#define SPIM_INST_IDX 1
#define MOSI_PIN NRF_GPIO_PIN_MAP(0, 7)
#define MISO_PIN 25
#define SCK_PIN NRF_GPIO_PIN_MAP(1, 2)   //1.02

void cs_select(uint32_t pin_number);
void cs_deselect(uint32_t pin_number);
void spi_write_dac1(uint8_t *tx_data, uint8_t *rx_data);
void spi_write_dac2(uint8_t *tx_data, uint8_t *rx_data);
void spi_init();
void update_dac1_amplitude(uint16_t amplitude);
void update_dac2_amplitude(uint16_t amplitude);

extern uint8_t dac1_buf_rx[DAC_RX_LEN];
extern uint8_t dac1_buf_tx[DAC_TX_LEN];
extern uint8_t dac2_buf_rx[DAC_RX_LEN];
extern uint8_t dac2_buf_tx[DAC_TX_LEN]; 
#endif
```

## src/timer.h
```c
#ifndef TIMER_H
#define TIMER_H

#include <nrfx_timer.h>
#include <zephyr/kernel.h>
#include <zephyr/device.h>

#define TIMER_INST_IDX 0
//This is the time between stim
#define DEFAULT_STIM_PERIOD 4000000
// This is the time between SPI transac on DAC1 and switching 1.03 off
#define DEFAULT_PULSE_WIDTH 1000000  // x1: Time after main event
// This is the time between switching 1.03 off and SPI transac on DAC2 
#define SWITCH_PERIOD 1000000  // x2: Time after EVENT1

typedef struct {
    uint32_t event1_max;
    uint32_t event2_max;
    uint32_t event3_max;
    uint32_t event0_error;
    uint32_t event0_max;
    uint32_t myerror;
    uint32_t mycounter;
} error_data;

void timer_init();
void get_error_data(error_data *data);
nrfx_timer_t measurement_timer_init();
void update_stim_frequency(uint16_t frequency_hz);
void update_pulse_width(uint16_t pulse_width_us);
#endif
```
